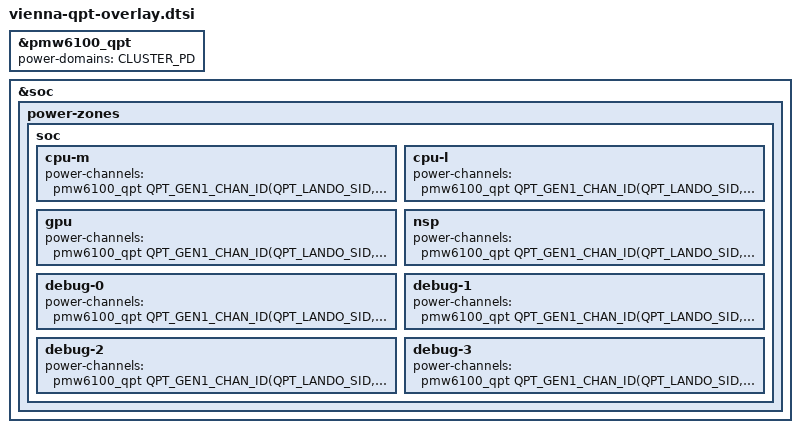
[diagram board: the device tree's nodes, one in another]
// SPDX-License-Identifier: BSD-3-Clause
/*
 * Copyright (c) Qualcomm Technologies, Inc. and/or its subsidiaries.
 */

#include <dt-bindings/soc/qcom,qpt-gen1-channels.h>

&pmw6100_qpt {
	status = "okay";
	power-domains = <&CLUSTER_PD>;
};

&soc {
	power-zones {
		soc {
			cpu-m {
				power-channels =
					<&pmw6100_qpt QPT_GEN1_CHAN_ID(QPT_LANDO_SID, QPT_S3_REG)>;
			};

			cpu-l {
				power-channels =
					<&pmw6100_qpt QPT_GEN1_CHAN_ID(QPT_LANDO_SID, QPT_S4_REG)>;
			};

			gpu {
				power-channels =
					<&pmw6100_qpt QPT_GEN1_CHAN_ID(QPT_LANDO_SID, QPT_S10_REG)>;
			};

			nsp {
				power-channels =
					<&pmw6100_qpt QPT_GEN1_CHAN_ID(QPT_LANDO_SID, QPT_S5_REG)>;
			};

			debug-0 {
				power-channels =
					<&pmw6100_qpt QPT_GEN1_CHAN_ID(QPT_LANDO_SID, QPT_S8_REG)>;
			};

			debug-1 {
				power-channels =
					<&pmw6100_qpt QPT_GEN1_CHAN_ID(QPT_LANDO_SID, QPT_S6_REG)>;
			};

			debug-2 {
				power-channels =
					<&pmw6100_qpt QPT_GEN1_CHAN_ID(QPT_LANDO_SID, QPT_S2_REG)>;
			};

			debug-3 {
				power-channels =
					<&pmw6100_qpt QPT_GEN1_CHAN_ID(QPT_LANDO_SID, QPT_S9_REG)>;
			};
		};
	};
};
